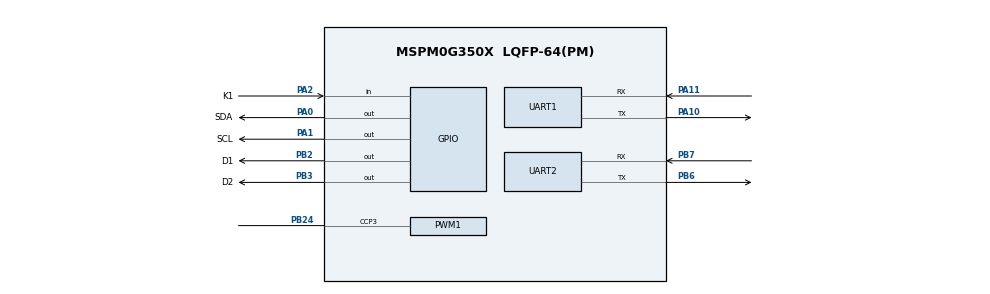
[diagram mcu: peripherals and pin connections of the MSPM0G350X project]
/**
 * @cliArgs --device "MSPM0G350X" --part "Default" --package "LQFP-64(PM)" --product "mspm0_sdk@2.02.00.05"
 * @versions {"tool":"1.21.1+3772"}
 */

/**
 * Import the modules used in this configuration.
 */
const GPIO    = scripting.addModule("/ti/driverlib/GPIO", {}, false);
const GPIO1   = GPIO.addInstance();
const GPIO2   = GPIO.addInstance();
const GPIO3   = GPIO.addInstance();
const I2C     = scripting.addModule("/ti/driverlib/I2C", {}, false);
const I2C1    = I2C.addInstance();
const PWM     = scripting.addModule("/ti/driverlib/PWM", {}, false);
const PWM1    = PWM.addInstance();
const SYSCTL  = scripting.addModule("/ti/driverlib/SYSCTL");
const SYSTICK = scripting.addModule("/ti/driverlib/SYSTICK");
const TIMER   = scripting.addModule("/ti/driverlib/TIMER", {}, false);
const TIMER1  = TIMER.addInstance();
const UART    = scripting.addModule("/ti/driverlib/UART", {}, false);
const UART1   = UART.addInstance();
const UART2   = UART.addInstance();

/**
 * Write custom configuration values to the imported modules.
 */
const divider9       = system.clockTree["UDIV"];
divider9.divideValue = 2;

const gate7  = system.clockTree["MFCLKGATE"];
gate7.enable = true;

const multiplier2         = system.clockTree["PLL_QDIV"];
multiplier2.multiplyValue = 5;

const mux8       = system.clockTree["HSCLKMUX"];
mux8.inputSelect = "HSCLKMUX_SYSPLL0";

GPIO1.$name                         = "LED";
GPIO1.port                          = "PORTB";
GPIO1.associatedPins.create(2);
GPIO1.associatedPins[0].$name       = "D1";
GPIO1.associatedPins[0].pin.$assign = "PB2";
GPIO1.associatedPins[1].$name       = "D2";
GPIO1.associatedPins[1].pin.$assign = "PB3";

const Board = scripting.addModule("/ti/driverlib/Board", {}, false);

GPIO2.$name                         = "KEY";
GPIO2.associatedPins[0].direction   = "INPUT";
GPIO2.associatedPins[0].$name       = "K1";
GPIO2.associatedPins[0].pin.$assign = "PA2";

GPIO3.$name                          = "MPU6050";
GPIO3.associatedPins.create(2);
GPIO3.associatedPins[0].$name        = "SCL";
GPIO3.associatedPins[0].initialValue = "SET";
GPIO3.associatedPins[0].ioStructure  = "OD";
GPIO3.associatedPins[0].pin.$assign  = "PA1";
GPIO3.associatedPins[1].$name        = "SDA";
GPIO3.associatedPins[1].initialValue = "SET";
GPIO3.associatedPins[1].ioStructure  = "OD";
GPIO3.associatedPins[1].pin.$assign  = "PA0";

I2C1.$name                             = "Sensor";
I2C1.basicEnableController             = true;
I2C1.basicControllerStandardBusSpeed   = "Fast";
I2C1.peripheral.$assign                = "I2C1";
I2C1.sdaPinConfig.hideOutputInversion  = scripting.forceWrite(false);
I2C1.sdaPinConfig.onlyInternalResistor = scripting.forceWrite(false);
I2C1.sdaPinConfig.passedPeripheralType = scripting.forceWrite("Digital");
I2C1.sdaPinConfig.$name                = "ti_driverlib_gpio_GPIOPinGeneric5";
I2C1.sclPinConfig.hideOutputInversion  = scripting.forceWrite(false);
I2C1.sclPinConfig.onlyInternalResistor = scripting.forceWrite(false);
I2C1.sclPinConfig.passedPeripheralType = scripting.forceWrite("Digital");
I2C1.sclPinConfig.$name                = "ti_driverlib_gpio_GPIOPinGeneric6";

PWM1.$name                      = "BUZZER";
PWM1.pwmMode                    = "EDGE_ALIGN_UP";
PWM1.ccIndex                    = [3];
PWM1.clockDivider               = 2;
PWM1.clockPrescale              = 16;
PWM1.peripheral.ccp3Pin.$assign = "PB24";
PWM1.PWM_CHANNEL_3.$name        = "ti_driverlib_pwm_PWMTimerCC0";
PWM1.ccp3PinConfig.$name        = "ti_driverlib_gpio_GPIOPinGeneric4";

SYSCTL.forceDefaultClkConfig = true;
SYSCTL.clockTreeEn           = true;

SYSTICK.periodEnable  = true;
SYSTICK.systickEnable = true;
SYSTICK.period        = 80;

TIMER1.$name              = "TIMER_0";
TIMER1.timerPeriod        = "1 ms";
TIMER1.timerClkDiv        = 8;
TIMER1.timerMode          = "PERIODIC";
TIMER1.interrupts         = ["ZERO"];
TIMER1.interruptPriority  = "0";
TIMER1.peripheral.$assign = "TIMG0";

UART1.$name                    = "UART_0";
UART1.uartClkSrc               = "MFCLK";
UART1.enabledInterrupts        = ["RX"];
UART1.targetBaudRate           = 115200;
UART1.interruptPriority        = "3";
UART1.peripheral.rxPin.$assign = "PA11";
UART1.peripheral.txPin.$assign = "PA10";
UART1.txPinConfig.$name        = "ti_driverlib_gpio_GPIOPinGeneric0";
UART1.rxPinConfig.$name        = "ti_driverlib_gpio_GPIOPinGeneric1";

UART2.targetBaudRate                   = 115200;
UART2.uartClkSrc                       = "MFCLK";
UART2.enabledInterrupts                = ["RX"];
UART2.$name                            = "Motor";
UART2.peripheral.rxPin.$assign         = "PB7";
UART2.peripheral.txPin.$assign         = "PB6";
UART2.txPinConfig.direction            = scripting.forceWrite("OUTPUT");
UART2.txPinConfig.hideOutputInversion  = scripting.forceWrite(false);
UART2.txPinConfig.onlyInternalResistor = scripting.forceWrite(false);
UART2.txPinConfig.passedPeripheralType = scripting.forceWrite("Digital");
UART2.txPinConfig.$name                = "ti_driverlib_gpio_GPIOPinGeneric2";
UART2.rxPinConfig.hideOutputInversion  = scripting.forceWrite(false);
UART2.rxPinConfig.onlyInternalResistor = scripting.forceWrite(false);
UART2.rxPinConfig.passedPeripheralType = scripting.forceWrite("Digital");
UART2.rxPinConfig.$name                = "ti_driverlib_gpio_GPIOPinGeneric3";

/**
 * Pinmux solution for unlocked pins/peripherals. This ensures that minor changes to the automatic solver in a future
 * version of the tool will not impact the pinmux you originally saw.  These lines can be completely deleted in order to
 * re-solve from scratch.
 */
Board.peripheral.$suggestSolution          = "DEBUGSS";
Board.peripheral.swclkPin.$suggestSolution = "PA20";
Board.peripheral.swdioPin.$suggestSolution = "PA19";
I2C1.peripheral.sdaPin.$suggestSolution    = "PA16";
I2C1.peripheral.sclPin.$suggestSolution    = "PA15";
PWM1.peripheral.$suggestSolution           = "TIMA0";
UART1.peripheral.$suggestSolution          = "UART0";
UART2.peripheral.$suggestSolution          = "UART1";
